AUTOSAR XML (schema 4-2-2)
package /ASW_COM_Pkg
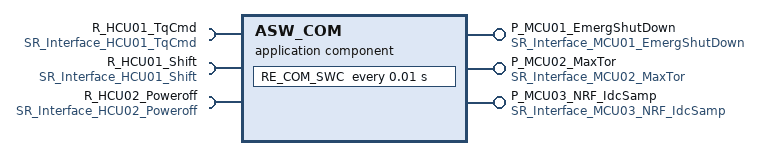
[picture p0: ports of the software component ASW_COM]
  application sw component type ASW_COM
    provide port P_MCU01_EmergShutDown: provided-interface=SR_Interface_MCU01_EmergShutDown
    provide port P_MCU02_MaxTor: provided-interface=SR_Interface_MCU02_MaxTor
    provide port P_MCU03_NRF_IdcSamp: provided-interface=SR_Interface_MCU03_NRF_IdcSamp
    require port R_HCU01_TqCmd: required-interface=SR_Interface_HCU01_TqCmd
    require port R_HCU01_Shift: required-interface=SR_Interface_HCU01_Shift
    require port R_HCU02_Poweroff: nonqueued-receiver-com-spec{data-element=DE_HCU02_Poweroff, alive-supervision=timeout=0.3}, required-interface=SR_Interface_HCU02_Poweroff
    behavior IB_ASW_COM
      timing event TE_RE_COM_SWC_10ms: start-on-event=RE_COM_SWC, period=0.01
      runnable RE_COM_SWC
        data-read-access-points:
          access VA_READ_HCU01_TqCmd: accessed-variable=R_HCU01_TqCmd.DE_HCU01_TqCmd
          access VA_READ_HCU01_Shift: accessed-variable=R_HCU01_Shift.DE_HCU01_Shift
          access VA_READ_HCU02_Poweroff: accessed-variable=R_HCU02_Poweroff.DE_HCU02_Poweroff
        data-write-access-points:
          access VA_WRITE_MCU01_EmergShutDown: accessed-variable=P_MCU01_EmergShutDown.DE_MCU01_EmergShutDown
          access VA_WRITE_MCU02_MaxTor: accessed-variable=P_MCU02_MaxTor.DE_MCU02_MaxTor
          access VA_WRITE_MCU03_NRF_IdcSamp: accessed-variable=P_MCU03_NRF_IdcSamp.DE_MCU03_NRF_IdcSamp
package /COM_Interface
  6 x sender receiver interface:
    SR_Interface_HCU01_Shift
      data DE_HCU01_Shift: type=Idt_uint8
    SR_Interface_HCU01_TqCmd
      data DE_HCU01_TqCmd: type=Idt_uint16
    SR_Interface_HCU02_Poweroff
      data DE_HCU02_Poweroff: type=Idt_boolean
    SR_Interface_MCU01_EmergShutDown
      data DE_MCU01_EmergShutDown: type=Idt_boolean
    SR_Interface_MCU02_MaxTor
      data DE_MCU02_MaxTor: type=Idt_uint16
    SR_Interface_MCU03_NRF_IdcSamp
      data DE_MCU03_NRF_IdcSamp: type=Idt_float32
package /DataTypes
  4 x impl type, all with category=VALUE:
    Idt_boolean
    Idt_uint8
    Idt_uint16
    Idt_float32
